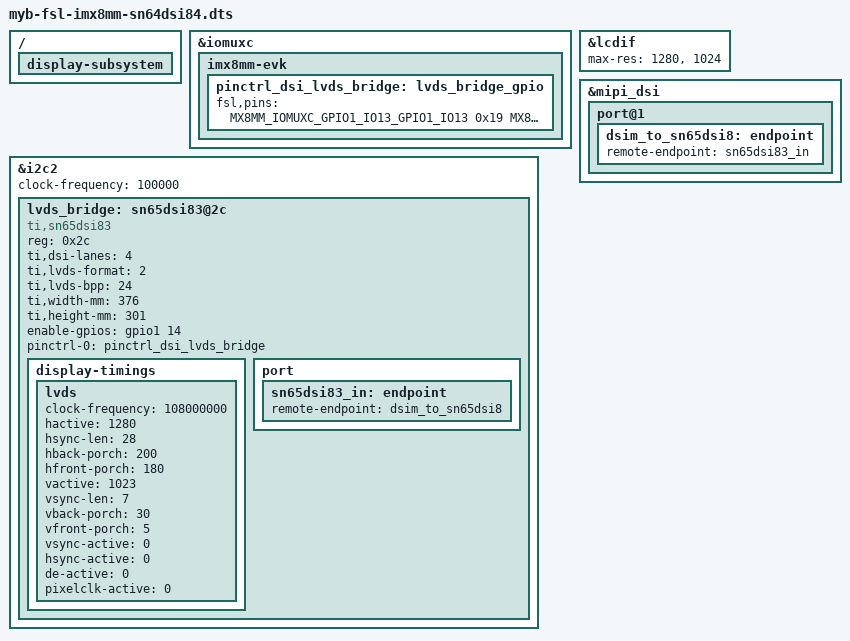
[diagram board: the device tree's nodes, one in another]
/*
 * Copyright 2019 MYiR Devices
 */
 
#include "myb-fsl-imx8mm-evk.dts"

/{
     display-subsystem {                                                                                
         status = "okay";
	};
};

&iomuxc {
        imx8mm-evk {
            pinctrl_dsi_lvds_bridge: lvds_bridge_gpio {
                fsl,pins = <
			MX8MM_IOMUXC_GPIO1_IO13_GPIO1_IO13       0x19
			MX8MM_IOMUXC_GPIO1_IO12_GPIO1_IO12       0x19
                >;
            };

        };

};

&lcdif{
	max-res = <1280>, <1024>;
	status = "okay";
};

&mipi_dsi {
        status = "okay";

        port@1 {
                dsim_to_sn65dsi8: endpoint {
                        remote-endpoint = <&sn65dsi83_in>;
                };
        };
};

&i2c2 {
    clock-frequency = <100000>;
    pinctrl-names = "default";
    status = "okay";

    lvds_bridge: sn65dsi83@2c {
        compatible = "ti,sn65dsi83";
        reg = <0x2c>;
        ti,dsi-lanes = <4>;
        ti,lvds-format = <2>;
        ti,lvds-bpp = <24>;
        ti,width-mm = <376>;
        ti,height-mm = <301>;

        enable-gpios = <&gpio1 14  GPIO_ACTIVE_HIGH>;
        pinctrl-names = "default";
        pinctrl-0 = <&pinctrl_dsi_lvds_bridge>;
        status = "okay";

       display-timings {
            lvds {
/*
                clock-frequency = <90000000>;
                hactive = <1280>;
                hsync-len = <54>;
                hback-porch = <75>;
                hfront-porch = <75>;
                vactive = <1024>;
                vsync-len = <10>;
                vback-porch = <10>;
                vfront-porch = <22>;

                vsync-active = <0>;
                hsync-active =<0>;
                de-active =<0>;
                pixelclk-active =<0>;
*/
                         clock-frequency = <108000000>;
                         hactive = <1280>;
                         hsync-len = <28>;
                         hback-porch = <200>;
                         hfront-porch = <180>;
                         vactive = <1023>;
                         vsync-len = <7>;
                         vback-porch = <30>;
                         vfront-porch = <5>;

                         vsync-active = <0>;
                         hsync-active =<0>;
                         de-active =<0>;
                         pixelclk-active =<0>;

            };
        };

        port {
            sn65dsi83_in: endpoint {
                remote-endpoint = <&dsim_to_sn65dsi8>;
            };
        };
    };

};

